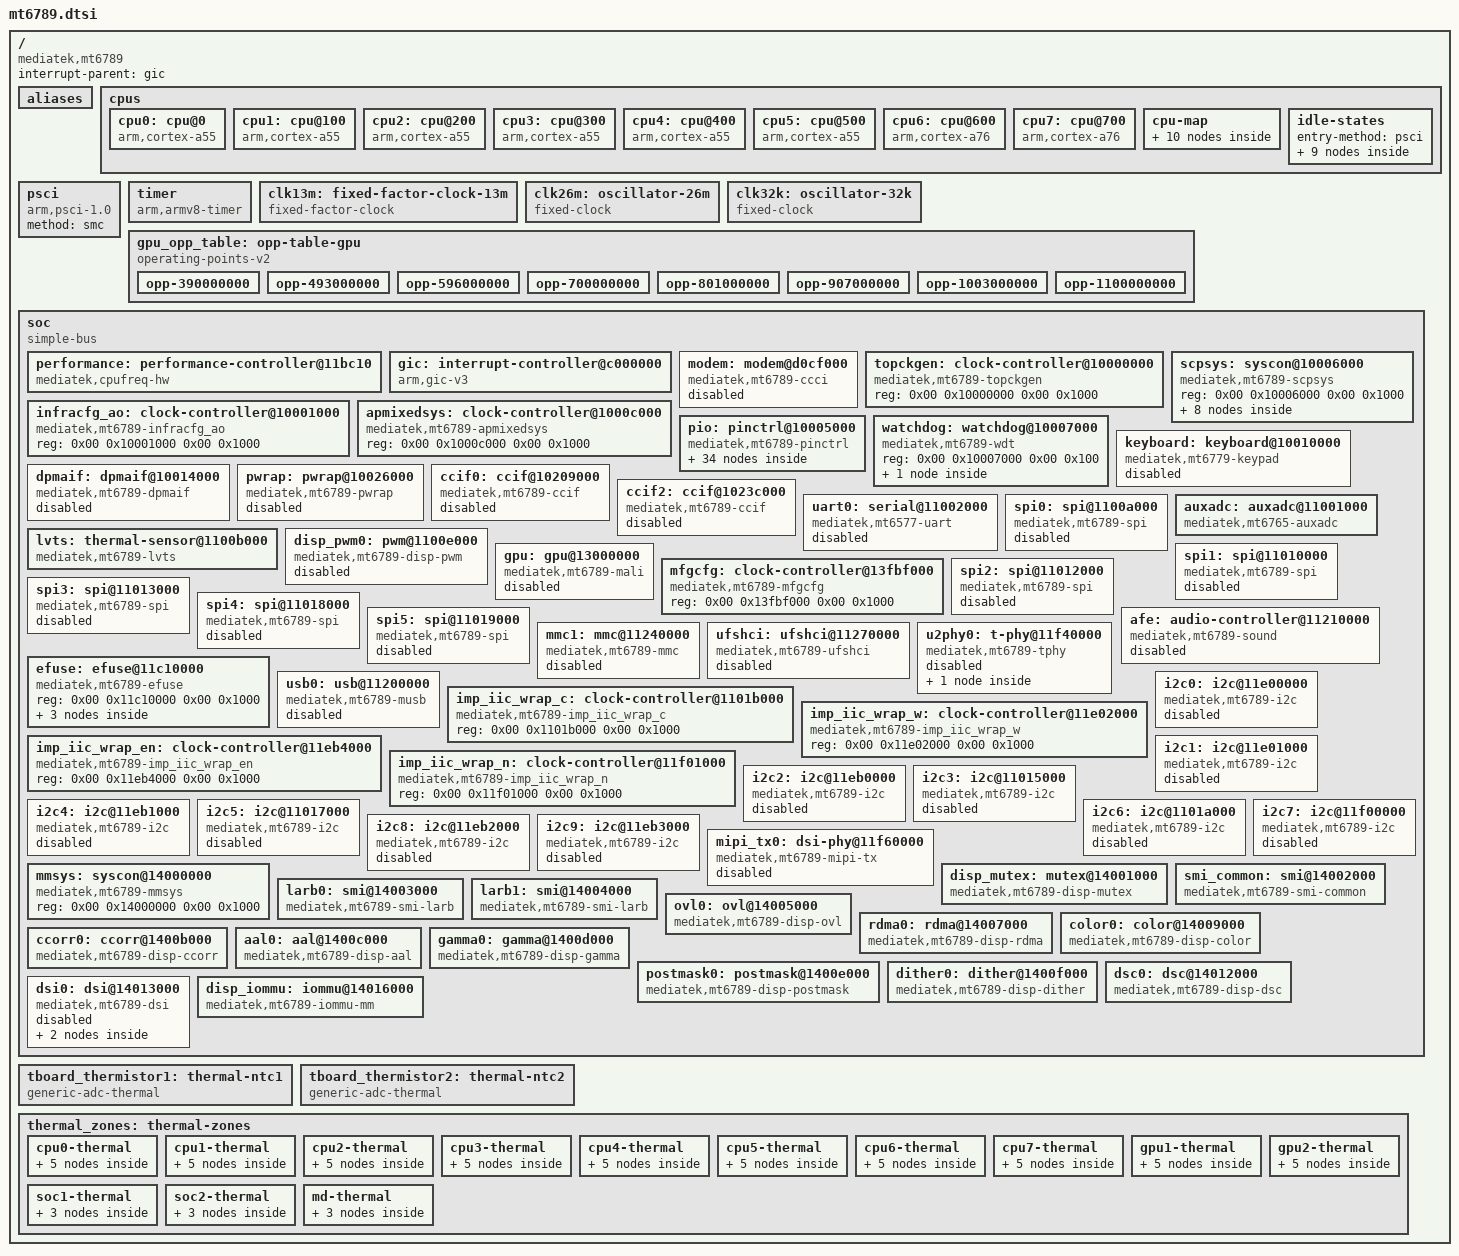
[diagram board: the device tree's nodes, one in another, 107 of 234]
// SPDX-License-Identifier: GPL-2.0-or-later
/*
 * MediaTek MT6789 (Helio G99) SoC base device tree — mainline shape.
 *
 * Board authority: Advan X1 stock artifacts (extracted/v5/dtb/main_dtb_0.dts,
 * dtbo_unpacked.dts). Every address/IRQ here is copied from those files; the
 * structure follows upstream mediatek dtsi conventions (mt8186 generation).
 *
 * P1 scope: CPU topology, GICv3, arch timer, PSCI, watchdog, UART0, and the
 * three clock controllers (topckgen, apmixedsys, infracfg_ao). UFS/USB/mphy/
 * scpsys nodes land in P2-P4 with their drivers.
 */

#include <dt-bindings/interrupt-controller/arm-gic.h>
#include <dt-bindings/interrupt-controller/irq.h>
#include <dt-bindings/clock/mt6789-clk.h>
#include <dt-bindings/memory/mediatek,mt6789-memory-port.h>
#include <dt-bindings/reset/mt6789-resets.h>
#include <dt-bindings/phy/phy.h>
#include <dt-bindings/pinctrl/mt65xx.h>
#include <dt-bindings/pinctrl/mt6789-pinfunc.h>
#include <dt-bindings/power/mt6789-power.h>
#include <dt-bindings/thermal/thermal.h>
#include <dt-bindings/thermal/mediatek,lvts-thermal.h>

/ {
	compatible = "mediatek,mt6789";
	interrupt-parent = <&gic>;
	#address-cells = <2>;
	#size-cells = <2>;

	aliases {
		serial0 = &uart0;
		spi0 = &spi0;
		spi1 = &spi1;
		spi2 = &spi2;
		spi3 = &spi3;
		spi4 = &spi4;
		spi5 = &spi5;
		ovl0 = &ovl0;
		rdma0 = &rdma0;
		color0 = &color0;
		ccorr0 = &ccorr0;
		aal0 = &aal0;
		gamma0 = &gamma0;
		postmask0 = &postmask0;
		dither0 = &dither0;
		dsi0 = &dsi0;
		mutex0 = &disp_mutex;
	};

	cpus {
		#address-cells = <1>;
		#size-cells = <0>;

		/*
		 * 6x Cortex-A55 (MPIDR 0x0-0x5, cluster 0) and
		 * 2x Cortex-A76 (MPIDR 0x6-0x7, cluster 1).
		 */
		cpu0: cpu@0 {
			device_type = "cpu";
			compatible = "arm,cortex-a55";
			reg = <0x000>;
			enable-method = "psci";
			capacity-dmips-mhz = <383>;
			performance-domains = <&performance 0>;
			cpu-idle-states = <&cpuoff_l &clusteroff_l &mcusysoff
					   &system_mem &system_pll &system_bus
					   &s2idle>;
			#cooling-cells = <2>;
		};

		cpu1: cpu@100 {
			device_type = "cpu";
			compatible = "arm,cortex-a55";
			reg = <0x100>;
			enable-method = "psci";
			capacity-dmips-mhz = <383>;
			performance-domains = <&performance 0>;
			cpu-idle-states = <&cpuoff_l &clusteroff_l &mcusysoff
					   &system_mem &system_pll &system_bus
					   &s2idle>;
			#cooling-cells = <2>;
		};

		cpu2: cpu@200 {
			device_type = "cpu";
			compatible = "arm,cortex-a55";
			reg = <0x200>;
			enable-method = "psci";
			capacity-dmips-mhz = <383>;
			performance-domains = <&performance 0>;
			cpu-idle-states = <&cpuoff_l &clusteroff_l &mcusysoff
					   &system_mem &system_pll &system_bus
					   &s2idle>;
			#cooling-cells = <2>;
		};

		cpu3: cpu@300 {
			device_type = "cpu";
			compatible = "arm,cortex-a55";
			reg = <0x300>;
			enable-method = "psci";
			capacity-dmips-mhz = <383>;
			performance-domains = <&performance 0>;
			cpu-idle-states = <&cpuoff_l &clusteroff_l &mcusysoff
					   &system_mem &system_pll &system_bus
					   &s2idle>;
			#cooling-cells = <2>;
		};

		cpu4: cpu@400 {
			device_type = "cpu";
			compatible = "arm,cortex-a55";
			reg = <0x400>;
			enable-method = "psci";
			capacity-dmips-mhz = <383>;
			performance-domains = <&performance 0>;
			cpu-idle-states = <&cpuoff_l &clusteroff_l &mcusysoff
					   &system_mem &system_pll &system_bus
					   &s2idle>;
			#cooling-cells = <2>;
		};

		cpu5: cpu@500 {
			device_type = "cpu";
			compatible = "arm,cortex-a55";
			reg = <0x500>;
			enable-method = "psci";
			capacity-dmips-mhz = <383>;
			performance-domains = <&performance 0>;
			cpu-idle-states = <&cpuoff_l &clusteroff_l &mcusysoff
					   &system_mem &system_pll &system_bus
					   &s2idle>;
			#cooling-cells = <2>;
		};

		cpu6: cpu@600 {
			device_type = "cpu";
			compatible = "arm,cortex-a76";
			reg = <0x600>;
			enable-method = "psci";
			capacity-dmips-mhz = <1024>;
			performance-domains = <&performance 1>;
			cpu-idle-states = <&cpuoff_b &clusteroff_b &mcusysoff
					   &system_mem &system_pll &system_bus
					   &s2idle>;
			#cooling-cells = <2>;
		};

		cpu7: cpu@700 {
			device_type = "cpu";
			compatible = "arm,cortex-a76";
			reg = <0x700>;
			enable-method = "psci";
			capacity-dmips-mhz = <1024>;
			performance-domains = <&performance 1>;
			cpu-idle-states = <&cpuoff_b &clusteroff_b &mcusysoff
					   &system_mem &system_pll &system_bus
					   &s2idle>;
			#cooling-cells = <2>;
		};

		cpu-map {
			cluster0 {
				core0 { cpu = <&cpu0>; };
				core1 { cpu = <&cpu1>; };
				core2 { cpu = <&cpu2>; };
				core3 { cpu = <&cpu3>; };
				core4 { cpu = <&cpu4>; };
				core5 { cpu = <&cpu5>; };
			};

			cluster1 {
				core0 { cpu = <&cpu6>; };
				core1 { cpu = <&cpu7>; };
			};
		};

		idle-states {
			entry-method = "psci";

			cpuoff_l: cpu-off-l {
				compatible = "arm,idle-state";
				arm,psci-suspend-param = <0x00010001>;
				local-timer-stop;
				entry-latency-us = <50>;
				exit-latency-us = <100>;
				min-residency-us = <1600>;
			};

			cpuoff_b: cpu-off-b {
				compatible = "arm,idle-state";
				arm,psci-suspend-param = <0x00010002>;
				local-timer-stop;
				entry-latency-us = <50>;
				exit-latency-us = <100>;
				min-residency-us = <1400>;
			};

			clusteroff_l: cluster-off-l {
				compatible = "arm,idle-state";
				arm,psci-suspend-param = <0x01010101>;
				local-timer-stop;
				entry-latency-us = <100>;
				exit-latency-us = <250>;
				min-residency-us = <2100>;
			};

			clusteroff_b: cluster-off-b {
				compatible = "arm,idle-state";
				arm,psci-suspend-param = <0x01010102>;
				local-timer-stop;
				entry-latency-us = <100>;
				exit-latency-us = <250>;
				min-residency-us = <1900>;
			};

			mcusysoff: cluster-mcusys-off {
				compatible = "arm,idle-state";
				arm,psci-suspend-param = <0x01010701>;
				local-timer-stop;
				entry-latency-us = <450>;
				exit-latency-us = <600>;
				min-residency-us = <4000>;
			};

			system_mem: cluster-system-mem {
				compatible = "arm,idle-state";
				arm,psci-suspend-param = <0x01010f01>;
				local-timer-stop;
				entry-latency-us = <700>;
				exit-latency-us = <850>;
				min-residency-us = <4000>;
			};

			system_pll: cluster-system-pll {
				compatible = "arm,idle-state";
				arm,psci-suspend-param = <0x01010f02>;
				local-timer-stop;
				entry-latency-us = <800>;
				exit-latency-us = <950>;
				min-residency-us = <4000>;
			};

			system_bus: cluster-system-bus {
				compatible = "arm,idle-state";
				arm,psci-suspend-param = <0x01010f03>;
				local-timer-stop;
				entry-latency-us = <1300>;
				exit-latency-us = <2800>;
				min-residency-us = <4000>;
			};

			s2idle: cluster-s2idle {
				compatible = "arm,idle-state";
				arm,psci-suspend-param = <0x01011f01>;
				local-timer-stop;
				entry-latency-us = <10000>;
				exit-latency-us = <10000>;
				min-residency-us = <0xffffffff>;
			};
		};
	};

	psci {
		compatible = "arm,psci-1.0", "arm,psci-0.2";
		method = "smc";
	};

	timer {
		compatible = "arm,armv8-timer";
		interrupt-parent = <&gic>;
		interrupts = <GIC_PPI 13 (GIC_CPU_MASK_SIMPLE(8) | IRQ_TYPE_LEVEL_LOW)>,
			     <GIC_PPI 14 (GIC_CPU_MASK_SIMPLE(8) | IRQ_TYPE_LEVEL_LOW)>,
			     <GIC_PPI 11 (GIC_CPU_MASK_SIMPLE(8) | IRQ_TYPE_LEVEL_LOW)>,
			     <GIC_PPI 10 (GIC_CPU_MASK_SIMPLE(8) | IRQ_TYPE_LEVEL_LOW)>;
		/* LK leaves the counter at 13 MHz (verified 2026-11-11). */
		clock-frequency = <13000000>;
	};

	clk13m: fixed-factor-clock-13m {
		compatible = "fixed-factor-clock";
		#clock-cells = <0>;
		clocks = <&clk26m>;
		clock-div = <2>;
		clock-mult = <1>;
		clock-output-names = "clk13m";
	};

	clk26m: oscillator-26m {
		compatible = "fixed-clock";
		#clock-cells = <0>;
		clock-frequency = <26000000>;
		clock-output-names = "clk26m";
	};

	clk32k: oscillator-32k {
		compatible = "fixed-clock";
		#clock-cells = <0>;
		clock-frequency = <32768>;
		clock-output-names = "clk32k";
	};

	gpu_opp_table: opp-table-gpu {
		compatible = "operating-points-v2";

		opp-390000000 {
			opp-hz = /bits/ 64 <390000000>;
			opp-microvolt = <675000>;
		};

		opp-493000000 {
			opp-hz = /bits/ 64 <493000000>;
			opp-microvolt = <687500>;
		};

		opp-596000000 {
			opp-hz = /bits/ 64 <596000000>;
			opp-microvolt = <693750>;
		};

		opp-700000000 {
			opp-hz = /bits/ 64 <700000000>;
			opp-microvolt = <700000>;
		};

		opp-801000000 {
			opp-hz = /bits/ 64 <801000000>;
			opp-microvolt = <756250>;
		};

		opp-907000000 {
			opp-hz = /bits/ 64 <907000000>;
			opp-microvolt = <806250>;
		};

		opp-1003000000 {
			opp-hz = /bits/ 64 <1003000000>;
			opp-microvolt = <856250>;
		};

		opp-1100000000 {
			opp-hz = /bits/ 64 <1100000000>;
			opp-microvolt = <900000>;
		};
	};

	soc: soc {
		compatible = "simple-bus";
		#address-cells = <2>;
		#size-cells = <2>;
		ranges;

		performance: performance-controller@11bc10 {
			compatible = "mediatek,cpufreq-hw";
			reg = <0x00 0x0011bc10 0x00 0x120>,
			      <0x00 0x0011bd30 0x00 0x120>;
			#performance-domain-cells = <1>;
		};

		gic: interrupt-controller@c000000 {
			compatible = "arm,gic-v3";
			#interrupt-cells = <3>;
			#address-cells = <2>;
			#size-cells = <2>;
			interrupt-controller;
			reg = <0x00 0x0c000000 0x00 0x00040000>, /* GICD */
			      <0x00 0x0c040000 0x00 0x00200000>; /* GICR */
			interrupts = <GIC_PPI 9 (GIC_CPU_MASK_SIMPLE(8) | IRQ_TYPE_LEVEL_HIGH)>;
		};

		modem: modem@d0cf000 {
			compatible = "mediatek,mt6789-ccci";
			reg = <0x00 0x0d0cf000 0x00 0x1000>;
			reg-names = "md-rgu";
			interrupts = <GIC_SPI 110 IRQ_TYPE_EDGE_RISING>;
			interrupt-names = "md-wdt";
			power-domains = <&spm MT6789_POWER_DOMAIN_MD>;
			mediatek,ccif = <&ccif0>;
			mediatek,ccif-scp = <&ccif2>;
			mediatek,dpmaif = <&dpmaif>;
			mediatek,scpsys = <&scpsys>;
			mediatek,infracfg = <&infracfg_ao>;
			mediatek,srclken-o1 = <0x200000>;
			mediatek,power-flow-config = <0x12>;
			status = "disabled";
		};

		topckgen: clock-controller@10000000 {
			compatible = "mediatek,mt6789-topckgen", "syscon";
			reg = <0x00 0x10000000 0x00 0x1000>;
			#clock-cells = <1>;
		};

		infracfg_ao: clock-controller@10001000 {
			compatible = "mediatek,mt6789-infracfg_ao", "syscon";
			reg = <0x00 0x10001000 0x00 0x1000>;
			#clock-cells = <1>;
			#reset-cells = <1>;
		};

		scpsys: syscon@10006000 {
			compatible = "mediatek,mt6789-scpsys", "syscon", "simple-mfd";
			reg = <0x00 0x10006000 0x00 0x1000>;

			/* System Power Manager */
			spm: power-controller {
				compatible = "mediatek,mt6789-power-controller";
				#address-cells = <1>;
				#size-cells = <0>;
				#power-domain-cells = <1>;

				/* power domain of the SoC */
				md: power-domain@0 {
					reg = <MT6789_POWER_DOMAIN_MD>;
					mediatek,infracfg = <&infracfg_ao>;
					#power-domain-cells = <0>;
				};

				mfg0: power-domain@2 {
					reg = <MT6789_POWER_DOMAIN_MFG0>;
					clocks = <&topckgen CLK_TOP_MFG_PLL_SEL>,
						 <&topckgen CLK_TOP_MFG_REF_SEL>;
					clock-names = "mfg", "alt";
					#address-cells = <1>;
					#size-cells = <0>;
					#power-domain-cells = <1>;

					mfg1: power-domain@3 {
						reg = <MT6789_POWER_DOMAIN_MFG1>;
						mediatek,infracfg = <&infracfg_ao>;
						#address-cells = <1>;
						#size-cells = <0>;
						#power-domain-cells = <1>;

						mfg2: power-domain@4 {
							reg = <MT6789_POWER_DOMAIN_MFG2>;
							#power-domain-cells = <0>;
						};

						mfg3: power-domain@5 {
							reg = <MT6789_POWER_DOMAIN_MFG3>;
							#power-domain-cells = <0>;
						};
					};
				};

				power-domain@10 {
					reg = <MT6789_POWER_DOMAIN_DISP>;
					clocks = <&topckgen CLK_TOP_DISP_SEL>,
						 <&mmsys CLK_MM_SMI_INFRA>,
						 <&mmsys CLK_MM_SMI_COMMON>,
						 <&mmsys CLK_MM_SMI_GALS>,
						 <&mmsys CLK_MM_SMI_IOMMU>,
						 <&mmsys CLK_MM_APB_BUS>,
						 <&mmsys CLK_MM_DISP_26M>;
					clock-names = "disp",
						      "subsys-smi-infra",
						      "subsys-smi-common",
						      "subsys-smi-gals",
						      "subsys-smi-iommu",
						      "subsys-apb-bus",
						      "subsys-disp-26m";
					mediatek,infracfg = <&infracfg_ao>;
					#power-domain-cells = <0>;
				};

				power-domain@11 {
					reg = <MT6789_POWER_DOMAIN_AUDIO>;
					clocks = <&topckgen CLK_TOP_AUD_INTBUS_SEL>,
						 <&infracfg_ao CLK_IFRAO_AUDIO_26M_BCLK>,
						 <&infracfg_ao CLK_IFRAO_AUDIO>;
					clock-names = "audio",
						      "subsys-audio-0",
						      "subsys-audio-1";
					mediatek,infracfg = <&infracfg_ao>;
					#power-domain-cells = <0>;
				};
			};
		};

		apmixedsys: clock-controller@1000c000 {
			compatible = "mediatek,mt6789-apmixedsys", "syscon";
			reg = <0x00 0x1000c000 0x00 0x1000>;
			#clock-cells = <1>;
		};

		pio: pinctrl@10005000 {
			compatible = "mediatek,mt6789-pinctrl";
			reg = <0x00 0x10005000 0x00 0x1000>,
			      <0x00 0x11c30000 0x00 0x1000>,
			      <0x00 0x11d10000 0x00 0x1000>,
			      <0x00 0x11d40000 0x00 0x1000>,
			      <0x00 0x11e20000 0x00 0x1000>,
			      <0x00 0x11e60000 0x00 0x1000>,
			      <0x00 0x11ea0000 0x00 0x1000>,
			      <0x00 0x1000b000 0x00 0x1000>;
			reg-names = "gpio",
				    "iocfg_rb",
				    "iocfg_bm",
				    "iocfg_br",
				    "iocfg_lm",
				    "iocfg_bl",
				    "iocfg_rt",
				    "eint";
			gpio-controller;
			#gpio-cells = <2>;
			gpio-ranges = <&pio 0 0 188>;
			interrupt-controller;
			#interrupt-cells = <2>;
			interrupts = <GIC_SPI 244 IRQ_TYPE_LEVEL_HIGH>;

			spi0_pins: spi0-default-pins {
				pins-bus {
					pinmux = <PINMUX_GPIO30__FUNC_SPI0_CLK>,
						 <PINMUX_GPIO31__FUNC_SPI0_CSB>,
						 <PINMUX_GPIO32__FUNC_SPI0_MO>,
						 <PINMUX_GPIO33__FUNC_SPI0_MI>;
					drive-strength = <2>;
					bias-disable;
				};
			};

			spi1_pins: spi1-default-pins {
				pins-bus {
					pinmux = <PINMUX_GPIO34__FUNC_SPI1_CLK>,
						 <PINMUX_GPIO35__FUNC_SPI1_CSB>,
						 <PINMUX_GPIO36__FUNC_SPI1_MO>,
						 <PINMUX_GPIO37__FUNC_SPI1_MI>;
					bias-disable;
				};
			};

			spi2_pins: spi2-default-pins {
				pins-bus {
					pinmux = <PINMUX_GPIO38__FUNC_SPI2_CLK>,
						 <PINMUX_GPIO39__FUNC_SPI2_CSB>,
						 <PINMUX_GPIO40__FUNC_SPI2_MO>,
						 <PINMUX_GPIO41__FUNC_SPI2_MI>;
					bias-disable;
				};
			};

			spi3_pins: spi3-default-pins {
				pins-bus {
					pinmux = <PINMUX_GPIO42__FUNC_SPI3_CLK>,
						 <PINMUX_GPIO43__FUNC_SPI3_CSB>,
						 <PINMUX_GPIO44__FUNC_SPI3_MO>,
						 <PINMUX_GPIO45__FUNC_SPI3_MI>;
					bias-disable;
				};
			};

			spi4_pins: spi4-default-pins {
				pins-bus {
					pinmux = <PINMUX_GPIO9__FUNC_SPI4_CLK>,
						 <PINMUX_GPIO10__FUNC_SPI4_CSB>,
						 <PINMUX_GPIO11__FUNC_SPI4_MO>,
						 <PINMUX_GPIO12__FUNC_SPI4_MI>;
					bias-disable;
				};
			};

			spi5_pins: spi5-default-pins {
				pins-bus {
					pinmux = <PINMUX_GPIO46__FUNC_SPI5_CLK>,
						 <PINMUX_GPIO47__FUNC_SPI5_CSB>,
						 <PINMUX_GPIO48__FUNC_SPI5_MO>,
						 <PINMUX_GPIO49__FUNC_SPI5_MI>;
					bias-disable;
				};
			};

			i2c0_pins: i2c0-default-pins {
				pins-bus {
					pinmux = <PINMUX_GPIO130__FUNC_SCL0>,
						 <PINMUX_GPIO131__FUNC_SDA0>;
					bias-pull-up = <MTK_PULL_SET_RSEL_011>;
					input-enable;
				};
			};

			i2c1_pins: i2c1-default-pins {
				pins-bus {
					pinmux = <PINMUX_GPIO132__FUNC_SCL1>,
						 <PINMUX_GPIO133__FUNC_SDA1>;
					bias-pull-up = <MTK_PULL_SET_RSEL_011>;
					input-enable;
				};
			};

			i2c2_pins: i2c2-default-pins {
				pins-bus {
					pinmux = <PINMUX_GPIO134__FUNC_SCL2>,
						 <PINMUX_GPIO135__FUNC_SDA2>;
					bias-pull-up = <MTK_PULL_SET_RSEL_011>;
					input-enable;
				};
			};

			i2c3_pins: i2c3-default-pins {
				pins-bus {
					pinmux = <PINMUX_GPIO136__FUNC_SCL3>,
						 <PINMUX_GPIO137__FUNC_SDA3>;
					bias-pull-up = <MTK_PULL_SET_RSEL_011>;
					input-enable;
				};
			};

			i2c4_pins: i2c4-default-pins {
				pins-bus {
					pinmux = <PINMUX_GPIO138__FUNC_SCL4>,
						 <PINMUX_GPIO139__FUNC_SDA4>;
					bias-pull-up = <MTK_PULL_SET_RSEL_011>;
					input-enable;
				};
			};

			i2c5_pins: i2c5-default-pins {
				pins-bus {
					pinmux = <PINMUX_GPIO140__FUNC_SCL5>,
						 <PINMUX_GPIO141__FUNC_SDA5>;
					bias-pull-up = <MTK_PULL_SET_RSEL_011>;
					input-enable;
				};
			};

			i2c6_pins: i2c6-default-pins {
				pins-bus {
					pinmux = <PINMUX_GPIO142__FUNC_SCL6>,
						 <PINMUX_GPIO143__FUNC_SDA6>;
					bias-pull-up = <MTK_PULL_SET_RSEL_011>;
					input-enable;
				};
			};

			i2c7_pins: i2c7-default-pins {
				pins-bus {
					pinmux = <PINMUX_GPIO144__FUNC_SCL7>,
						 <PINMUX_GPIO145__FUNC_SDA7>;
					bias-pull-up = <MTK_PULL_SET_RSEL_011>;
					input-enable;
				};
			};

			i2c8_pins: i2c8-default-pins {
				pins-bus {
					pinmux = <PINMUX_GPIO146__FUNC_SCL8>,
						 <PINMUX_GPIO147__FUNC_SDA8>;
					bias-pull-up = <MTK_PULL_SET_RSEL_011>;
					input-enable;
				};
			};

			i2c9_pins: i2c9-default-pins {
				pins-bus {
					pinmux = <PINMUX_GPIO148__FUNC_SCL9>,
						 <PINMUX_GPIO149__FUNC_SDA9>;
					bias-pull-up = <MTK_PULL_SET_RSEL_011>;
					input-enable;
				};
			};

			disp_pwm0_pins: disp-pwm0-default-pins {
				pins-bus {
					pinmux = <PINMUX_GPIO84__FUNC_DISP_PWM>;
				};
			};
		};

		watchdog: watchdog@10007000 {
			compatible = "mediatek,mt6789-wdt", "mediatek,mt6589-wdt",
				     "syscon", "simple-mfd";
			reg = <0x00 0x10007000 0x00 0x100>;
			#reset-cells = <1>;

			reboot-mode {
				compatible = "syscon-reboot-mode";
				offset = <0x24>;
				mask = <0x0f>;
				mode-charger = <0x01>;
				mode-recovery = <0x02>;
				mode-bootloader = <0x03>;
				mode-dm-verity-dev-corrupt = <0x04>;
				mode-kpoc = <0x05>;
				mode-ddr-reserve = <0x06>;
				mode-meta = <0x07>;
				mode-rpmbpk = <0x08>;
			};
		};

		keyboard: keyboard@10010000 {
			compatible = "mediatek,mt6779-keypad";
			reg = <0x00 0x10010000 0x00 0x1000>;
			interrupts = <GIC_SPI 106 IRQ_TYPE_EDGE_RISING>;
			clocks = <&clk26m>;
			clock-names = "kpd";
			status = "disabled";
		};

		dpmaif: dpmaif@10014000 {
			compatible = "mediatek,mt6789-dpmaif";
			reg = <0x00 0x10014000 0x00 0x1000>,
			      <0x00 0x10014400 0x00 0x1000>,
			      <0x00 0x1022d000 0x00 0x1000>,
			      <0x00 0x1022d100 0x00 0x1000>,
			      <0x00 0x1022d400 0x00 0x1000>,
			      <0x00 0x1022c000 0x00 0x1000>,
			      <0x00 0x1022e000 0x00 0x1000>;
			reg-names = "ao-ul", "ao-dl", "pd-ul", "pd-dl",
				    "pd-misc", "pd-md-misc", "pd-sram";
			interrupts = <GIC_SPI 241 IRQ_TYPE_LEVEL_HIGH>;
			clocks = <&infracfg_ao CLK_IFRAO_DPMAIF_MAIN>,
				 <&infracfg_ao CLK_IFRAO_CLDMA_BCLK>;
			clock-names = "dpmaif", "bclk";
			status = "disabled";
		};

		pwrap: pwrap@10026000 {
			compatible = "mediatek,mt6789-pwrap", "syscon";
			reg = <0x00 0x10026000 0x00 0x1000>;
			reg-names = "pwrap";
			interrupts = <GIC_SPI 252 IRQ_TYPE_LEVEL_HIGH>;
			clocks = <&infracfg_ao CLK_IFRAO_PMIC_AP>,
				 <&infracfg_ao CLK_IFRAO_PMIC_TMR>;
			clock-names = "spi", "wrap";
			status = "disabled";
		};

		ccif0: ccif@10209000 {
			compatible = "mediatek,mt6789-ccif";
			reg = <0x00 0x10209000 0x00 0x1000>,
			      <0x00 0x1020a000 0x00 0x1000>;
			reg-names = "ap", "md";
			interrupts = <GIC_SPI 226 IRQ_TYPE_LEVEL_HIGH>,
				     <GIC_SPI 227 IRQ_TYPE_LEVEL_HIGH>;
			clocks = <&infracfg_ao CLK_IFRAO_CCIF_AP>,
				 <&infracfg_ao CLK_IFRAO_CCIF_MD>,
				 <&infracfg_ao CLK_IFRAO_CCIF1_AP>,
				 <&infracfg_ao CLK_IFRAO_CCIF1_MD>,
				 <&infracfg_ao CLK_IFRAO_CCIF4_MD>,
				 <&infracfg_ao CLK_IFRAO_CCIF5_MD>;
			clock-names = "ccif-ap", "ccif-md", "ccif1-ap",
				      "ccif1-md", "ccif4-md", "ccif5-md";
			mediatek,ccif-sram-size = <0x200>;
			status = "disabled";
		};

		ccif2: ccif@1023c000 {
			compatible = "mediatek,mt6789-ccif";
			reg = <0x00 0x1023c000 0x00 0x1000>,
			      <0x00 0x1023d000 0x00 0x1000>;
			reg-names = "ap", "md";
			clocks = <&infracfg_ao CLK_IFRAO_CCIF2_AP>,
				 <&infracfg_ao CLK_IFRAO_CCIF2_MD>;
			clock-names = "ccif2-ap", "ccif2-md";
			status = "disabled";
		};

		uart0: serial@11002000 {
			compatible = "mediatek,mt6577-uart";
			reg = <0x00 0x11002000 0x00 0x1000>;
			interrupts = <GIC_SPI 141 IRQ_TYPE_LEVEL_HIGH>;
			clocks = <&clk26m>, <&infracfg_ao CLK_IFRAO_UART0>;
			clock-names = "baud", "bus";
			status = "disabled";
		};

		spi0: spi@1100a000 {
			compatible = "mediatek,mt6789-spi", "mediatek,mt6765-spi";
			#address-cells = <1>;
			#size-cells = <0>;
			reg = <0x00 0x1100a000 0x00 0x100>;
			interrupts = <GIC_SPI 191 IRQ_TYPE_LEVEL_HIGH>;
			clocks = <&topckgen CLK_TOP_MSDCPLL_D2>,
				 <&topckgen CLK_TOP_SPI_SEL>,
				 <&infracfg_ao CLK_IFRAO_SPI0>;
			clock-names = "parent-clk", "sel-clk", "spi-clk";
			mediatek,pad-select = <0>;
			status = "disabled";
		};

		auxadc: auxadc@11001000 {
			compatible = "mediatek,mt6765-auxadc";
			reg = <0x00 0x11001000 0x00 0x1000>;
			clocks = <&infracfg_ao CLK_IFRAO_AUXADC>;
			clock-names = "main";
			#io-channel-cells = <1>;
		};

		lvts: thermal-sensor@1100b000 {
			compatible = "mediatek,mt6789-lvts";
			reg = <0x00 0x1100b000 0x00 0x1000>;
			interrupts = <GIC_SPI 201 IRQ_TYPE_LEVEL_HIGH>;
			clocks = <&infracfg_ao CLK_IFRAO_THERM>;
			resets = <&infracfg_ao MT6789_INFRA_RST0_THERM_CTRL_SWRST>;
			nvmem-cells = <&lvts_e_data>;
			nvmem-cell-names = "lvts-calib-data-1";
			#thermal-sensor-cells = <1>;
		};

		disp_pwm0: pwm@1100e000 {
			compatible = "mediatek,mt6789-disp-pwm";
			reg = <0x00 0x1100e000 0x00 0x1000>;
			interrupts = <GIC_SPI 203 IRQ_TYPE_LEVEL_HIGH>;
			#pwm-cells = <2>;
			clocks = <&topckgen CLK_TOP_DISP_PWM>,
				 <&infracfg_ao CLK_IFRAO_DISP_PWM>;
			clock-names = "main", "mm";
			pinctrl-names = "default";
			pinctrl-0 = <&disp_pwm0_pins>;
			status = "disabled";
		};

		gpu: gpu@13000000 {
			compatible = "mediatek,mt6789-mali",
				     "arm,mali-valhall-jm";
			reg = <0x00 0x13000000 0x00 0x4000>;
			interrupts = <GIC_SPI 398 IRQ_TYPE_LEVEL_HIGH>,
				     <GIC_SPI 397 IRQ_TYPE_LEVEL_HIGH>,
				     <GIC_SPI 396 IRQ_TYPE_LEVEL_HIGH>;
			interrupt-names = "job", "mmu", "gpu";
			clocks = <&mfgcfg CLK_MFGCFG_BG3D>;
			power-domains = <&spm MT6789_POWER_DOMAIN_MFG2>,
					<&spm MT6789_POWER_DOMAIN_MFG3>;
			power-domain-names = "core0", "core1";
			operating-points-v2 = <&gpu_opp_table>;
			#cooling-cells = <2>;
			status = "disabled";
		};

		mfgcfg: clock-controller@13fbf000 {
			compatible = "mediatek,mt6789-mfgcfg", "syscon";
			reg = <0x00 0x13fbf000 0x00 0x1000>;
			#clock-cells = <1>;
		};

		spi1: spi@11010000 {
			compatible = "mediatek,mt6789-spi", "mediatek,mt6765-spi";
			#address-cells = <1>;
			#size-cells = <0>;
			reg = <0x00 0x11010000 0x00 0x100>;
			interrupts = <GIC_SPI 192 IRQ_TYPE_LEVEL_HIGH>;
			clocks = <&topckgen CLK_TOP_MSDCPLL_D2>,
				 <&topckgen CLK_TOP_SPI_SEL>,
				 <&infracfg_ao CLK_IFRAO_SPI1>;
			clock-names = "parent-clk", "sel-clk", "spi-clk";
			mediatek,pad-select = <0>;
			status = "disabled";
		};

		spi2: spi@11012000 {
			compatible = "mediatek,mt6789-spi", "mediatek,mt6765-spi";
			#address-cells = <1>;
			#size-cells = <0>;
			reg = <0x00 0x11012000 0x00 0x100>;
			interrupts = <GIC_SPI 193 IRQ_TYPE_LEVEL_HIGH>;
			clocks = <&topckgen CLK_TOP_MSDCPLL_D2>,
				 <&topckgen CLK_TOP_SPI_SEL>,
				 <&infracfg_ao CLK_IFRAO_SPI2>;
			clock-names = "parent-clk", "sel-clk", "spi-clk";
			mediatek,pad-select = <0>;
			status = "disabled";
		};

		spi3: spi@11013000 {
			compatible = "mediatek,mt6789-spi", "mediatek,mt6765-spi";
			#address-cells = <1>;
			#size-cells = <0>;
			reg = <0x00 0x11013000 0x00 0x100>;
			interrupts = <GIC_SPI 194 IRQ_TYPE_LEVEL_HIGH>;
			clocks = <&topckgen CLK_TOP_MSDCPLL_D2>,
				 <&topckgen CLK_TOP_SPI_SEL>,
				 <&infracfg_ao CLK_IFRAO_SPI3>;
			clock-names = "parent-clk", "sel-clk", "spi-clk";
			mediatek,pad-select = <0>;
			status = "disabled";
		};

		spi4: spi@11018000 {
			compatible = "mediatek,mt6789-spi", "mediatek,mt6765-spi";
			#address-cells = <1>;
			#size-cells = <0>;
			reg = <0x00 0x11018000 0x00 0x100>;
			interrupts = <GIC_SPI 195 IRQ_TYPE_LEVEL_HIGH>;
			clocks = <&topckgen CLK_TOP_MSDCPLL_D2>,
				 <&topckgen CLK_TOP_SPI_SEL>,
				 <&infracfg_ao CLK_IFRAO_SPI4>;
			clock-names = "parent-clk", "sel-clk", "spi-clk";
			mediatek,pad-select = <0>;
			status = "disabled";
		};

		spi5: spi@11019000 {
			compatible = "mediatek,mt6789-spi", "mediatek,mt6765-spi";
			#address-cells = <1>;
			#size-cells = <0>;
			reg = <0x00 0x11019000 0x00 0x100>;
			interrupts = <GIC_SPI 196 IRQ_TYPE_LEVEL_HIGH>;
			clocks = <&topckgen CLK_TOP_MSDCPLL_D2>,
				 <&topckgen CLK_TOP_SPI_SEL>,
				 <&infracfg_ao CLK_IFRAO_SPI5>;
			clock-names = "parent-clk", "sel-clk", "spi-clk";
			mediatek,pad-select = <0>;
			status = "disabled";
		};

		afe: audio-controller@11210000 {
			compatible = "mediatek,mt6789-sound";
			reg = <0x00 0x11210000 0x00 0x2000>;
			interrupts = <GIC_SPI 234 IRQ_TYPE_LEVEL_HIGH>;
			power-domains = <&spm MT6789_POWER_DOMAIN_AUDIO>;
			mediatek,apmixedsys = <&apmixedsys>;
			mediatek,infracfg = <&infracfg_ao>;
			mediatek,topckgen = <&topckgen>;
			clocks = <&infracfg_ao CLK_IFRAO_AUDIO>,
				 <&infracfg_ao CLK_IFRAO_AUDIO_26M_BCLK>,
				 <&topckgen CLK_TOP_AUDIO_SEL>,
				 <&topckgen CLK_TOP_AUD_INTBUS_SEL>,
				 <&topckgen CLK_TOP_MAINPLL_D4_D4>,
				 <&topckgen CLK_TOP_AUD_1_SEL>,
				 <&topckgen CLK_TOP_APLL1>,
				 <&topckgen CLK_TOP_AUD_2_SEL>,
				 <&topckgen CLK_TOP_APLL2>,
				 <&topckgen CLK_TOP_AUD_ENGEN1_SEL>,
				 <&topckgen CLK_TOP_APLL1_D8>,
				 <&topckgen CLK_TOP_AUD_ENGEN2_SEL>,
				 <&topckgen CLK_TOP_APLL2_D8>,
				 <&topckgen CLK_TOP_APLL_I2S0_MCK_SEL>,
				 <&topckgen CLK_TOP_APLL_I2S1_MCK_SEL>,
				 <&topckgen CLK_TOP_APLL_I2S2_MCK_SEL>,
				 <&topckgen CLK_TOP_APLL_I2S4_MCK_SEL>,
				 <&topckgen CLK_TOP_APLL_I2S5_MCK_SEL>,
				 <&topckgen CLK_TOP_APLL12_CK_DIV0>,
				 <&topckgen CLK_TOP_APLL12_CK_DIV1>,
				 <&topckgen CLK_TOP_APLL12_CK_DIV2>,
				 <&topckgen CLK_TOP_APLL12_CK_DIV4>,
				 <&topckgen CLK_TOP_APLL12_CK_DIV5>,
				 <&topckgen CLK_TOP_AUDIO_H_SEL>,
				 <&topckgen CLK_TOP_TCK_26M_MX9>;
			clock-names = "aud_infra_clk",
				      "mtkaif_26m_clk",
				      "top_mux_audio",
				      "top_mux_audio_int",
				      "top_mainpll_d2_d4",
				      "top_mux_aud_1",
				      "top_apll1_ck",
				      "top_mux_aud_2",
				      "top_apll2_ck",
				      "top_mux_aud_eng1",
				      "top_apll1_d8",
				      "top_mux_aud_eng2",
				      "top_apll2_d8",
				      "top_i2s0_m_sel",
				      "top_i2s1_m_sel",
				      "top_i2s2_m_sel",
				      "top_i2s4_m_sel",
				      "top_tdm_m_sel",
				      "top_apll12_div0",
				      "top_apll12_div1",
				      "top_apll12_div2",
				      "top_apll12_div4",
				      "top_apll12_div_tdm",
				      "top_mux_audio_h",
				      "top_clk26m_clk";
			status = "disabled";
		};

		mmc1: mmc@11240000 {
			compatible = "mediatek,mt6789-mmc", "mediatek,mt8183-mmc";
			reg = <0x00 0x11240000 0x00 0x1000>,
			      <0x00 0x11ef0000 0x00 0x1000>;
			interrupts = <GIC_SPI 135 IRQ_TYPE_LEVEL_HIGH>;
			clocks = <&topckgen CLK_TOP_MSDC30_1_SEL>,
				 <&infracfg_ao CLK_IFRAO_MSDC1>,
				 <&infracfg_ao CLK_IFRAO_MSDC1_SRC>;
			clock-names = "source", "hclk", "source_cg";
			assigned-clocks = <&topckgen CLK_TOP_MSDC30_1_SEL>;
			assigned-clock-parents = <&topckgen CLK_TOP_MSDCPLL_D2>;
			status = "disabled";
		};

		ufshci: ufshci@11270000 {
			compatible = "mediatek,mt6789-ufshci", "mediatek,mt8183-ufshci";
			reg = <0x00 0x11270000 0x00 0x2300>;
			interrupts = <GIC_SPI 137 IRQ_TYPE_LEVEL_HIGH>;
			clocks = <&infracfg_ao CLK_IFRAO_UFS>,
				 <&infracfg_ao CLK_IFRAO_UFS_SAP_BCLK>,
				 <&infracfg_ao CLK_IFRAO_UNIPRO_TICK>,
				 <&infracfg_ao CLK_IFRAO_UNIPRO_SYSCLK>,
				 <&infracfg_ao CLK_IFRAO_UFS_AES>,
				 <&topckgen CLK_TOP_AES_UFSFDE_SEL>,
				 <&topckgen CLK_TOP_UFS_SEL>;
			clock-names = "ufs", "ufs_mp", "unipro_tick",
				      "unipro_sys", "ufs_aes",
				      "ufsfde_ck", "ufs_ck";
			freq-table-hz = <0 0>, <0 0>, <0 0>, <0 0>, <0 0>,
					<0 0>, <0 0>;
			resets = <&infracfg_ao MT6789_INFRA_RST1_UFS_SWRST>,
				 <&infracfg_ao MT6789_INFRA_RST2_UFS_UNIPRO_SWRST>,
				 <&infracfg_ao MT6789_INFRA_RST3_UFS_AES_SWRST>;
			reset-names = "hci_rst", "unipro_rst", "crypto_rst";
			mediatek,ufs-disable-mcq;
			status = "disabled";
		};

		efuse: efuse@11c10000 {
			compatible = "mediatek,mt6789-efuse", "mediatek,efuse";
			reg = <0x00 0x11c10000 0x00 0x1000>;
			#address-cells = <1>;
			#size-cells = <1>;

			socinfo-data1@4c {
				reg = <0x4c 0x4>;
			};

			socinfo-data2@50 {
				reg = <0x50 0x4>;
			};

			lvts_e_data: lvts-calib@1a4 {
				reg = <0x1a4 0x34>;
			};
		};

		u2phy0: t-phy@11f40000 {
			compatible = "mediatek,mt6789-tphy", "mediatek,generic-tphy-v2";
			#address-cells = <1>;
			#size-cells = <1>;
			ranges = <0x0 0x0 0x11f40000 0x1000>;
			status = "disabled";

			u2port0: usb-phy@0 {
				reg = <0x0 0x700>;
				clocks = <&clk26m>;
				clock-names = "ref";
				#phy-cells = <1>;
				mediatek,eye-vrt = <4>;
				mediatek,eye-term = <4>;
				mediatek,discth = <7>;
			};
		};

		usb0: usb@11200000 {
			compatible = "mediatek,mt6789-musb", "mediatek,mtk-musb";
			reg = <0x00 0x11200000 0x00 0x10000>;
			interrupts = <GIC_SPI 128 IRQ_TYPE_LEVEL_HIGH>;
			interrupt-names = "mc";
			clocks = <&infracfg_ao CLK_IFRAO_SSUSB>,
				 <&topckgen CLK_TOP_USB_TOP_SEL>,
				 <&apmixedsys CLK_APMIXED_USBPLL>;
			clock-names = "main", "mcu", "univpll";
			phys = <&u2port0 PHY_TYPE_USB2>;
			dr_mode = "peripheral";
			status = "disabled";
		};

		imp_iic_wrap_c: clock-controller@1101b000 {
			compatible = "mediatek,mt6789-imp_iic_wrap_c", "syscon";
			reg = <0x00 0x1101b000 0x00 0x1000>;
			#clock-cells = <1>;
		};

		imp_iic_wrap_w: clock-controller@11e02000 {
			compatible = "mediatek,mt6789-imp_iic_wrap_w", "syscon";
			reg = <0x00 0x11e02000 0x00 0x1000>;
			#clock-cells = <1>;
		};

		imp_iic_wrap_en: clock-controller@11eb4000 {
			compatible = "mediatek,mt6789-imp_iic_wrap_en", "syscon";
			reg = <0x00 0x11eb4000 0x00 0x1000>;
			#clock-cells = <1>;
		};

		imp_iic_wrap_n: clock-controller@11f01000 {
			compatible = "mediatek,mt6789-imp_iic_wrap_n", "syscon";
			reg = <0x00 0x11f01000 0x00 0x1000>;
			#clock-cells = <1>;
		};

		i2c0: i2c@11e00000 {
			compatible = "mediatek,mt6789-i2c";
			reg = <0x00 0x11e00000 0x00 0x1000>,
			      <0x00 0x10217080 0x00 0x80>;
			interrupts = <GIC_SPI 144 IRQ_TYPE_LEVEL_HIGH>;
			clocks = <&imp_iic_wrap_w CLK_IMPW_AP_CLOCK_I2C0>,
				 <&infracfg_ao CLK_IFRAO_AP_DMA>;
			clock-names = "main", "dma";
			clock-div = <1>;
			#address-cells = <1>;
			#size-cells = <0>;
			status = "disabled";
		};

		i2c1: i2c@11e01000 {
			compatible = "mediatek,mt6789-i2c";
			reg = <0x00 0x11e01000 0x00 0x1000>,
			      <0x00 0x10217100 0x00 0x80>;
			interrupts = <GIC_SPI 145 IRQ_TYPE_LEVEL_HIGH>;
			clocks = <&imp_iic_wrap_w CLK_IMPW_AP_CLOCK_I2C1>,
				 <&infracfg_ao CLK_IFRAO_AP_DMA>;
			clock-names = "main", "dma";
			clock-div = <1>;
			#address-cells = <1>;
			#size-cells = <0>;
			status = "disabled";
		};

		i2c2: i2c@11eb0000 {
			compatible = "mediatek,mt6789-i2c";
			reg = <0x00 0x11eb0000 0x00 0x1000>,
			      <0x00 0x10217180 0x00 0x80>;
			interrupts = <GIC_SPI 146 IRQ_TYPE_LEVEL_HIGH>;
			clocks = <&imp_iic_wrap_en CLK_IMPEN_AP_CLOCK_I2C2>,
				 <&infracfg_ao CLK_IFRAO_AP_DMA>;
			clock-names = "main", "dma";
			clock-div = <1>;
			#address-cells = <1>;
			#size-cells = <0>;
			status = "disabled";
		};

		i2c3: i2c@11015000 {
			compatible = "mediatek,mt6789-i2c";
			reg = <0x00 0x11015000 0x00 0x1000>,
			      <0x00 0x10217280 0x00 0x80>;
			interrupts = <GIC_SPI 147 IRQ_TYPE_LEVEL_HIGH>;
			clocks = <&imp_iic_wrap_c CLK_IMPC_AP_CLOCK_I2C3>,
				 <&infracfg_ao CLK_IFRAO_AP_DMA>;
			clock-names = "main", "dma";
			clock-div = <1>;
			#address-cells = <1>;
			#size-cells = <0>;
			status = "disabled";
		};

		i2c4: i2c@11eb1000 {
			compatible = "mediatek,mt6789-i2c";
			reg = <0x00 0x11eb1000 0x00 0x1000>,
			      <0x00 0x10217300 0x00 0x80>;
			interrupts = <GIC_SPI 148 IRQ_TYPE_LEVEL_HIGH>;
			clocks = <&imp_iic_wrap_en CLK_IMPEN_AP_CLOCK_I2C4>,
				 <&infracfg_ao CLK_IFRAO_AP_DMA>;
			clock-names = "main", "dma";
			clock-div = <1>;
			#address-cells = <1>;
			#size-cells = <0>;
			status = "disabled";
		};

		i2c5: i2c@11017000 {
			compatible = "mediatek,mt6789-i2c";
			reg = <0x00 0x11017000 0x00 0x1000>,
			      <0x00 0x10217400 0x00 0x80>;
			interrupts = <GIC_SPI 149 IRQ_TYPE_LEVEL_HIGH>;
			clocks = <&imp_iic_wrap_c CLK_IMPC_AP_CLOCK_I2C5>,
				 <&infracfg_ao CLK_IFRAO_AP_DMA>;
			clock-names = "main", "dma";
			clock-div = <1>;
			#address-cells = <1>;
			#size-cells = <0>;
			status = "disabled";
		};

		i2c6: i2c@1101a000 {
			compatible = "mediatek,mt6789-i2c";
			reg = <0x00 0x1101a000 0x00 0x1000>,
			      <0x00 0x10217480 0x00 0x80>;
			interrupts = <GIC_SPI 150 IRQ_TYPE_LEVEL_HIGH>;
			clocks = <&imp_iic_wrap_c CLK_IMPC_AP_CLOCK_I2C6>,
				 <&infracfg_ao CLK_IFRAO_AP_DMA>;
			clock-names = "main", "dma";
			clock-div = <1>;
			#address-cells = <1>;
			#size-cells = <0>;
			status = "disabled";
		};

		i2c7: i2c@11f00000 {
			compatible = "mediatek,mt6789-i2c";
			reg = <0x00 0x11f00000 0x00 0x1000>,
			      <0x00 0x10217500 0x00 0x80>;
			interrupts = <GIC_SPI 151 IRQ_TYPE_LEVEL_HIGH>;
			clocks = <&imp_iic_wrap_n CLK_IMPN_AP_CLOCK_I2C7>,
				 <&infracfg_ao CLK_IFRAO_AP_DMA>;
			clock-names = "main", "dma";
			clock-div = <1>;
			#address-cells = <1>;
			#size-cells = <0>;
			status = "disabled";
		};

		i2c8: i2c@11eb2000 {
			compatible = "mediatek,mt6789-i2c";
			reg = <0x00 0x11eb2000 0x00 0x1000>,
			      <0x00 0x10217600 0x00 0x80>;
			interrupts = <GIC_SPI 152 IRQ_TYPE_LEVEL_HIGH>;
			clocks = <&imp_iic_wrap_en CLK_IMPEN_AP_CLOCK_I2C8>,
				 <&infracfg_ao CLK_IFRAO_AP_DMA>;
			clock-names = "main", "dma";
			clock-div = <1>;
			#address-cells = <1>;
			#size-cells = <0>;
			status = "disabled";
		};

		i2c9: i2c@11eb3000 {
			compatible = "mediatek,mt6789-i2c";
			reg = <0x00 0x11eb3000 0x00 0x1000>,
			      <0x00 0x10217700 0x00 0x80>;
			interrupts = <GIC_SPI 153 IRQ_TYPE_LEVEL_HIGH>;
			clocks = <&imp_iic_wrap_en CLK_IMPEN_AP_CLOCK_I2C9>,
				 <&infracfg_ao CLK_IFRAO_AP_DMA>;
			clock-names = "main", "dma";
			clock-div = <1>;
			#address-cells = <1>;
			#size-cells = <0>;
			status = "disabled";
		};

		mipi_tx0: dsi-phy@11f60000 {
			compatible = "mediatek,mt6789-mipi-tx", "mediatek,mt8183-mipi-tx";
			reg = <0x00 0x11f60000 0x00 0x1000>;
			clocks = <&clk26m>;
			#clock-cells = <0>;
			#phy-cells = <0>;
			clock-output-names = "mipi_tx0_pll";
			status = "disabled";
		};

		mmsys: syscon@14000000 {
			compatible = "mediatek,mt6789-mmsys", "syscon";
			reg = <0x00 0x14000000 0x00 0x1000>;
			#clock-cells = <1>;
			#reset-cells = <1>;
		};

		disp_mutex: mutex@14001000 {
			compatible = "mediatek,mt6789-disp-mutex";
			reg = <0x00 0x14001000 0x00 0x1000>;
			clocks = <&mmsys CLK_MM_DISP_MUTEX0>;
			interrupts = <GIC_SPI 285 IRQ_TYPE_LEVEL_HIGH>;
			power-domains = <&spm MT6789_POWER_DOMAIN_DISP>;
		};

		smi_common: smi@14002000 {
			compatible = "mediatek,mt6789-smi-common";
			reg = <0x00 0x14002000 0x00 0x1000>;
			clocks = <&mmsys CLK_MM_SMI_COMMON>,
				 <&mmsys CLK_MM_SMI_COMMON>,
				 <&mmsys CLK_MM_SMI_GALS>,
				 <&mmsys CLK_MM_SMI_GALS>;
			clock-names = "apb", "smi", "gals0", "gals1";
			power-domains = <&spm MT6789_POWER_DOMAIN_DISP>;
		};

		larb0: smi@14003000 {
			compatible = "mediatek,mt6789-smi-larb";
			reg = <0x00 0x14003000 0x00 0x1000>;
			clocks = <&mmsys CLK_MM_SMI_COMMON>,
				 <&mmsys CLK_MM_SMI_COMMON>;
			clock-names = "apb", "smi";
			mediatek,larb-id = <0>;
			mediatek,smi = <&smi_common>;
			power-domains = <&spm MT6789_POWER_DOMAIN_DISP>;
		};

		larb1: smi@14004000 {
			compatible = "mediatek,mt6789-smi-larb";
			reg = <0x00 0x14004000 0x00 0x1000>;
			clocks = <&mmsys CLK_MM_SMI_COMMON>,
				 <&mmsys CLK_MM_SMI_COMMON>;
			clock-names = "apb", "smi";
			mediatek,larb-id = <1>;
			mediatek,smi = <&smi_common>;
			power-domains = <&spm MT6789_POWER_DOMAIN_DISP>;
		};

		ovl0: ovl@14005000 {
			compatible = "mediatek,mt6789-disp-ovl", "mediatek,mt8192-disp-ovl";
			reg = <0x00 0x14005000 0x00 0x1000>;
			clocks = <&mmsys CLK_MM_DISP_OVL0>;
			interrupts = <GIC_SPI 287 IRQ_TYPE_LEVEL_HIGH>;
			iommus = <&disp_iommu M4U_PORT_L0_OVL_RDMA0_HDR>,
				 <&disp_iommu M4U_PORT_L0_OVL_RDMA0>;
			power-domains = <&spm MT6789_POWER_DOMAIN_DISP>;
		};

		rdma0: rdma@14007000 {
			compatible = "mediatek,mt6789-disp-rdma", "mediatek,mt8183-disp-rdma";
			reg = <0x00 0x14007000 0x00 0x1000>;
			clocks = <&mmsys CLK_MM_DISP_RDMA0>;
			interrupts = <GIC_SPI 289 IRQ_TYPE_LEVEL_HIGH>;
			iommus = <&disp_iommu M4U_PORT_L1_DISP_RDMA0>;
			power-domains = <&spm MT6789_POWER_DOMAIN_DISP>;
		};

		color0: color@14009000 {
			compatible = "mediatek,mt6789-disp-color", "mediatek,mt8173-disp-color";
			reg = <0x00 0x14009000 0x00 0x1000>;
			clocks = <&mmsys CLK_MM_DISP_COLOR0>;
			interrupts = <GIC_SPI 291 IRQ_TYPE_LEVEL_HIGH>;
			power-domains = <&spm MT6789_POWER_DOMAIN_DISP>;
		};

		ccorr0: ccorr@1400b000 {
			compatible = "mediatek,mt6789-disp-ccorr", "mediatek,mt8192-disp-ccorr";
			reg = <0x00 0x1400b000 0x00 0x1000>;
			clocks = <&mmsys CLK_MM_DISP_CCORR0>;
			interrupts = <GIC_SPI 292 IRQ_TYPE_LEVEL_HIGH>;
			power-domains = <&spm MT6789_POWER_DOMAIN_DISP>;
		};

		aal0: aal@1400c000 {
			compatible = "mediatek,mt6789-disp-aal", "mediatek,mt8183-disp-aal";
			reg = <0x00 0x1400c000 0x00 0x1000>;
			clocks = <&mmsys CLK_MM_DISP_AAL0>;
			interrupts = <GIC_SPI 294 IRQ_TYPE_LEVEL_HIGH>;
			power-domains = <&spm MT6789_POWER_DOMAIN_DISP>;
		};

		gamma0: gamma@1400d000 {
			compatible = "mediatek,mt6789-disp-gamma", "mediatek,mt8195-disp-gamma";
			reg = <0x00 0x1400d000 0x00 0x1000>;
			clocks = <&mmsys CLK_MM_DISP_GAMMA0>;
			interrupts = <GIC_SPI 295 IRQ_TYPE_LEVEL_HIGH>;
			power-domains = <&spm MT6789_POWER_DOMAIN_DISP>;
		};

		postmask0: postmask@1400e000 {
			compatible = "mediatek,mt6789-disp-postmask",
				     "mediatek,mt8192-disp-postmask";
			reg = <0x00 0x1400e000 0x00 0x1000>;
			clocks = <&mmsys CLK_MM_DISP_POSTMASK0>;
			interrupts = <GIC_SPI 296 IRQ_TYPE_LEVEL_HIGH>;
			power-domains = <&spm MT6789_POWER_DOMAIN_DISP>;
		};

		dither0: dither@1400f000 {
			compatible = "mediatek,mt6789-disp-dither", "mediatek,mt8183-disp-dither";
			reg = <0x00 0x1400f000 0x00 0x1000>;
			clocks = <&mmsys CLK_MM_DISP_DITHER0>;
			interrupts = <GIC_SPI 297 IRQ_TYPE_LEVEL_HIGH>;
			power-domains = <&spm MT6789_POWER_DOMAIN_DISP>;
		};

		dsc0: dsc@14012000 {
			compatible = "mediatek,mt6789-disp-dsc", "mediatek,mt8195-disp-dsc";
			reg = <0x00 0x14012000 0x00 0x1000>;
			clocks = <&mmsys CLK_MM_DISP_DSC_WRAP0>;
			interrupts = <GIC_SPI 300 IRQ_TYPE_LEVEL_HIGH>;
			power-domains = <&spm MT6789_POWER_DOMAIN_DISP>;
		};

		dsi0: dsi@14013000 {
			compatible = "mediatek,mt6789-dsi";
			reg = <0x00 0x14013000 0x00 0x1000>;
			clocks = <&mmsys CLK_MM_DSI0>,
				 <&mmsys CLK_MM_DSI0_DSI_CK_DOMAIN>,
				 <&mipi_tx0>;
			clock-names = "engine", "digital", "hs";
			interrupts = <GIC_SPI 301 IRQ_TYPE_LEVEL_HIGH>;
			power-domains = <&spm MT6789_POWER_DOMAIN_DISP>;
			phys = <&mipi_tx0>;
			phy-names = "dphy";
			status = "disabled";

			port {
				dsi0_out: endpoint {
				};
			};
		};

		disp_iommu: iommu@14016000 {
			compatible = "mediatek,mt6789-iommu-mm";
			reg = <0x00 0x14016000 0x00 0x1000>;
			interrupts = <GIC_SPI 303 IRQ_TYPE_LEVEL_HIGH>;
			clocks = <&mmsys CLK_MM_SMI_IOMMU>;
			clock-names = "bclk";
			power-domains = <&spm MT6789_POWER_DOMAIN_DISP>;
			mediatek,larbs = <&larb0>, <&larb1>;
			#iommu-cells = <1>;
		};
	};

	tboard_thermistor1: thermal-ntc1 {
		compatible = "generic-adc-thermal";
		#thermal-sensor-cells = <0>;
		io-channels = <&auxadc 0>;
		io-channel-names = "sensor-channel";
		temperature-lookup-table = <
			(-40000) 1760 (-39000) 1757 (-38000) 1754
			(-37000) 1751 (-36000) 1747 (-35000) 1744
			(-34000) 1740 (-33000) 1736 (-32000) 1731
			(-31000) 1727 (-30000) 1722 (-29000) 1716
			(-28000) 1711 (-27000) 1705 (-26000) 1699
			(-25000) 1693 (-24000) 1686 (-23000) 1679
			(-22000) 1672 (-21000) 1664 (-20000) 1656
			(-19000) 1648 (-18000) 1639 (-17000) 1630
			(-16000) 1620 (-15000) 1610 (-14000) 1599
			(-13000) 1588 (-12000) 1577 (-11000) 1565
			(-10000) 1553 (-9000) 1540 (-8000) 1527
			(-7000) 1514 (-6000) 1500 (-5000) 1485
			(-4000) 1470 (-3000) 1455 (-2000) 1439
			(-1000) 1423 (0) 1406 (1000) 1389
			(2000) 1372 (3000) 1354 (4000) 1335
			(5000) 1317 (6000) 1298 (7000) 1279
			(8000) 1259 (9000) 1239 (10000) 1219
			(11000) 1198 (12000) 1178 (13000) 1157
			(14000) 1136 (15000) 1115 (16000) 1093
			(17000) 1072 (18000) 1050 (19000) 1029
			(20000) 1007 (21000) 986 (22000) 964
			(23000) 943 (24000) 921 (25000) 900
			(26000) 879 (27000) 858 (28000) 837
			(29000) 816 (30000) 796 (31000) 775
			(32000) 755 (33000) 736 (34000) 716
			(35000) 697 (36000) 678 (37000) 659
			(38000) 641 (39000) 623 (40000) 605
			(41000) 588 (42000) 571 (43000) 555
			(44000) 538 (45000) 523 (46000) 507
			(47000) 492 (48000) 477 (49000) 463
			(50000) 449 (51000) 435 (52000) 422
			(53000) 409 (54000) 396 (55000) 384
			(56000) 372 (57000) 360 (58000) 349
			(59000) 338 (60000) 327 (61000) 317
			(62000) 307 (63000) 297 (64000) 288
			(65000) 279 (66000) 270 (67000) 261
			(68000) 253 (69000) 245 (70000) 237
			(71000) 230 (72000) 222 (73000) 215
			(74000) 209 (75000) 202 (76000) 196
			(77000) 189 (78000) 183 (79000) 178
			(80000) 172 (81000) 167 (82000) 161
			(83000) 156 (84000) 151 (85000) 147
			(86000) 142 (87000) 138 (88000) 133
			(89000) 129 (90000) 125 (91000) 121
			(92000) 118 (93000) 114 (94000) 111
			(95000) 107 (96000) 104 (97000) 101
			(98000) 98 (99000) 95 (100000) 92
			(101000) 89 (102000) 87 (103000) 84
			(104000) 81 (105000) 79 (106000) 77
			(107000) 74 (108000) 72 (109000) 70
			(110000) 68 (111000) 66 (112000) 64
			(113000) 62 (114000) 61 (115000) 59
			(116000) 57 (117000) 56 (118000) 54
			(119000) 52 (120000) 51 (121000) 50
			(122000) 48 (123000) 47 (124000) 46
			(125000) 44
		>;
	};

	tboard_thermistor2: thermal-ntc2 {
		compatible = "generic-adc-thermal";
		#thermal-sensor-cells = <0>;
		io-channels = <&auxadc 1>;
		io-channel-names = "sensor-channel";
		temperature-lookup-table = <
			(-40000) 1760 (-39000) 1757 (-38000) 1754
			(-37000) 1751 (-36000) 1747 (-35000) 1744
			(-34000) 1740 (-33000) 1736 (-32000) 1731
			(-31000) 1727 (-30000) 1722 (-29000) 1716
			(-28000) 1711 (-27000) 1705 (-26000) 1699
			(-25000) 1693 (-24000) 1686 (-23000) 1679
			(-22000) 1672 (-21000) 1664 (-20000) 1656
			(-19000) 1648 (-18000) 1639 (-17000) 1630
			(-16000) 1620 (-15000) 1610 (-14000) 1599
			(-13000) 1588 (-12000) 1577 (-11000) 1565
			(-10000) 1553 (-9000) 1540 (-8000) 1527
			(-7000) 1514 (-6000) 1500 (-5000) 1485
			(-4000) 1470 (-3000) 1455 (-2000) 1439
			(-1000) 1423 (0) 1406 (1000) 1389
			(2000) 1372 (3000) 1354 (4000) 1335
			(5000) 1317 (6000) 1298 (7000) 1279
			(8000) 1259 (9000) 1239 (10000) 1219
			(11000) 1198 (12000) 1178 (13000) 1157
			(14000) 1136 (15000) 1115 (16000) 1093
			(17000) 1072 (18000) 1050 (19000) 1029
			(20000) 1007 (21000) 986 (22000) 964
			(23000) 943 (24000) 921 (25000) 900
			(26000) 879 (27000) 858 (28000) 837
			(29000) 816 (30000) 796 (31000) 775
			(32000) 755 (33000) 736 (34000) 716
			(35000) 697 (36000) 678 (37000) 659
			(38000) 641 (39000) 623 (40000) 605
			(41000) 588 (42000) 571 (43000) 555
			(44000) 538 (45000) 523 (46000) 507
			(47000) 492 (48000) 477 (49000) 463
			(50000) 449 (51000) 435 (52000) 422
			(53000) 409 (54000) 396 (55000) 384
			(56000) 372 (57000) 360 (58000) 349
			(59000) 338 (60000) 327 (61000) 317
			(62000) 307 (63000) 297 (64000) 288
			(65000) 279 (66000) 270 (67000) 261
			(68000) 253 (69000) 245 (70000) 237
			(71000) 230 (72000) 222 (73000) 215
			(74000) 209 (75000) 202 (76000) 196
			(77000) 189 (78000) 183 (79000) 178
			(80000) 172 (81000) 167 (82000) 161
			(83000) 156 (84000) 151 (85000) 147
			(86000) 142 (87000) 138 (88000) 133
			(89000) 129 (90000) 125 (91000) 121
			(92000) 118 (93000) 114 (94000) 111
			(95000) 107 (96000) 104 (97000) 101
			(98000) 98 (99000) 95 (100000) 92
			(101000) 89 (102000) 87 (103000) 84
			(104000) 81 (105000) 79 (106000) 77
			(107000) 74 (108000) 72 (109000) 70
			(110000) 68 (111000) 66 (112000) 64
			(113000) 62 (114000) 61 (115000) 59
			(116000) 57 (117000) 56 (118000) 54
			(119000) 52 (120000) 51 (121000) 50
			(122000) 48 (123000) 47 (124000) 46
			(125000) 44
		>;
	};

	thermal_zones: thermal-zones {
		cpu0-thermal {
			polling-delay = <1000>;
			polling-delay-passive = <150>;
			thermal-sensors = <&lvts MT6789_LITTLE_CPU0>;

			trips {
				cpu0_alert: trip-alert {
					temperature = <85000>;
					hysteresis = <2000>;
					type = "passive";
				};

				cpu0_crit: trip-crit {
					temperature = <113500>;
					hysteresis = <2000>;
					type = "critical";
				};
			};

			cooling-maps {
				map0 {
					trip = <&cpu0_alert>;
					cooling-device = <&cpu0 THERMAL_NO_LIMIT THERMAL_NO_LIMIT>,
							 <&cpu1 THERMAL_NO_LIMIT THERMAL_NO_LIMIT>,
							 <&cpu2 THERMAL_NO_LIMIT THERMAL_NO_LIMIT>,
							 <&cpu3 THERMAL_NO_LIMIT THERMAL_NO_LIMIT>,
							 <&cpu4 THERMAL_NO_LIMIT THERMAL_NO_LIMIT>,
							 <&cpu5 THERMAL_NO_LIMIT THERMAL_NO_LIMIT>;
				};
			};
		};

		cpu1-thermal {
			polling-delay = <1000>;
			polling-delay-passive = <150>;
			thermal-sensors = <&lvts MT6789_LITTLE_CPU1>;

			trips {
				cpu1_alert: trip-alert {
					temperature = <85000>;
					hysteresis = <2000>;
					type = "passive";
				};

				cpu1_crit: trip-crit {
					temperature = <113500>;
					hysteresis = <2000>;
					type = "critical";
				};
			};

			cooling-maps {
				map0 {
					trip = <&cpu1_alert>;
					cooling-device = <&cpu0 THERMAL_NO_LIMIT THERMAL_NO_LIMIT>,
							 <&cpu1 THERMAL_NO_LIMIT THERMAL_NO_LIMIT>,
							 <&cpu2 THERMAL_NO_LIMIT THERMAL_NO_LIMIT>,
							 <&cpu3 THERMAL_NO_LIMIT THERMAL_NO_LIMIT>,
							 <&cpu4 THERMAL_NO_LIMIT THERMAL_NO_LIMIT>,
							 <&cpu5 THERMAL_NO_LIMIT THERMAL_NO_LIMIT>;
				};
			};
		};

		cpu2-thermal {
			polling-delay = <1000>;
			polling-delay-passive = <150>;
			thermal-sensors = <&lvts MT6789_LITTLE_CPU2>;

			trips {
				cpu2_alert: trip-alert {
					temperature = <85000>;
					hysteresis = <2000>;
					type = "passive";
				};

				cpu2_crit: trip-crit {
					temperature = <113500>;
					hysteresis = <2000>;
					type = "critical";
				};
			};

			cooling-maps {
				map0 {
					trip = <&cpu2_alert>;
					cooling-device = <&cpu0 THERMAL_NO_LIMIT THERMAL_NO_LIMIT>,
							 <&cpu1 THERMAL_NO_LIMIT THERMAL_NO_LIMIT>,
							 <&cpu2 THERMAL_NO_LIMIT THERMAL_NO_LIMIT>,
							 <&cpu3 THERMAL_NO_LIMIT THERMAL_NO_LIMIT>,
							 <&cpu4 THERMAL_NO_LIMIT THERMAL_NO_LIMIT>,
							 <&cpu5 THERMAL_NO_LIMIT THERMAL_NO_LIMIT>;
				};
			};
		};

		cpu3-thermal {
			polling-delay = <1000>;
			polling-delay-passive = <150>;
			thermal-sensors = <&lvts MT6789_LITTLE_CPU3>;

			trips {
				cpu3_alert: trip-alert {
					temperature = <85000>;
					hysteresis = <2000>;
					type = "passive";
				};

				cpu3_crit: trip-crit {
					temperature = <113500>;
					hysteresis = <2000>;
					type = "critical";
				};
			};

			cooling-maps {
				map0 {
					trip = <&cpu3_alert>;
					cooling-device = <&cpu0 THERMAL_NO_LIMIT THERMAL_NO_LIMIT>,
							 <&cpu1 THERMAL_NO_LIMIT THERMAL_NO_LIMIT>,
							 <&cpu2 THERMAL_NO_LIMIT THERMAL_NO_LIMIT>,
							 <&cpu3 THERMAL_NO_LIMIT THERMAL_NO_LIMIT>,
							 <&cpu4 THERMAL_NO_LIMIT THERMAL_NO_LIMIT>,
							 <&cpu5 THERMAL_NO_LIMIT THERMAL_NO_LIMIT>;
				};
			};
		};

		cpu4-thermal {
			polling-delay = <1000>;
			polling-delay-passive = <150>;
			thermal-sensors = <&lvts MT6789_BIG_CPU0>;

			trips {
				cpu4_alert: trip-alert {
					temperature = <85000>;
					hysteresis = <2000>;
					type = "passive";
				};

				cpu4_crit: trip-crit {
					temperature = <113500>;
					hysteresis = <2000>;
					type = "critical";
				};
			};

			cooling-maps {
				map0 {
					trip = <&cpu4_alert>;
					cooling-device = <&cpu6 THERMAL_NO_LIMIT THERMAL_NO_LIMIT>,
							 <&cpu7 THERMAL_NO_LIMIT THERMAL_NO_LIMIT>;
				};
			};
		};

		cpu5-thermal {
			polling-delay = <1000>;
			polling-delay-passive = <150>;
			thermal-sensors = <&lvts MT6789_BIG_CPU1>;

			trips {
				cpu5_alert: trip-alert {
					temperature = <85000>;
					hysteresis = <2000>;
					type = "passive";
				};

				cpu5_crit: trip-crit {
					temperature = <113500>;
					hysteresis = <2000>;
					type = "critical";
				};
			};

			cooling-maps {
				map0 {
					trip = <&cpu5_alert>;
					cooling-device = <&cpu6 THERMAL_NO_LIMIT THERMAL_NO_LIMIT>,
							 <&cpu7 THERMAL_NO_LIMIT THERMAL_NO_LIMIT>;
				};
			};
		};

		cpu6-thermal {
			polling-delay = <1000>;
			polling-delay-passive = <150>;
			thermal-sensors = <&lvts MT6789_BIG_CPU2>;

			trips {
				cpu6_alert: trip-alert {
					temperature = <85000>;
					hysteresis = <2000>;
					type = "passive";
				};

				cpu6_crit: trip-crit {
					temperature = <113500>;
					hysteresis = <2000>;
					type = "critical";
				};
			};

			cooling-maps {
				map0 {
					trip = <&cpu6_alert>;
					cooling-device = <&cpu6 THERMAL_NO_LIMIT THERMAL_NO_LIMIT>,
							 <&cpu7 THERMAL_NO_LIMIT THERMAL_NO_LIMIT>;
				};
			};
		};

		cpu7-thermal {
			polling-delay = <1000>;
			polling-delay-passive = <150>;
			thermal-sensors = <&lvts MT6789_BIG_CPU3>;

			trips {
				cpu7_alert: trip-alert {
					temperature = <85000>;
					hysteresis = <2000>;
					type = "passive";
				};

				cpu7_crit: trip-crit {
					temperature = <113500>;
					hysteresis = <2000>;
					type = "critical";
				};
			};

			cooling-maps {
				map0 {
					trip = <&cpu7_alert>;
					cooling-device = <&cpu6 THERMAL_NO_LIMIT THERMAL_NO_LIMIT>,
							 <&cpu7 THERMAL_NO_LIMIT THERMAL_NO_LIMIT>;
				};
			};
		};

		gpu1-thermal {
			polling-delay = <1000>;
			polling-delay-passive = <150>;
			thermal-sensors = <&lvts MT6789_GPU0>;

			trips {
				gpu1_alert: trip-alert {
					temperature = <85000>;
					hysteresis = <2000>;
					type = "passive";
				};

				gpu1_crit: trip-crit {
					temperature = <113500>;
					hysteresis = <2000>;
					type = "critical";
				};
			};

			cooling-maps {
				map0 {
					trip = <&gpu1_alert>;
					cooling-device = <&gpu THERMAL_NO_LIMIT THERMAL_NO_LIMIT>;
				};
			};
		};

		gpu2-thermal {
			polling-delay = <1000>;
			polling-delay-passive = <150>;
			thermal-sensors = <&lvts MT6789_GPU1>;

			trips {
				gpu2_alert: trip-alert {
					temperature = <85000>;
					hysteresis = <2000>;
					type = "passive";
				};

				gpu2_crit: trip-crit {
					temperature = <113500>;
					hysteresis = <2000>;
					type = "critical";
				};
			};

			cooling-maps {
				map0 {
					trip = <&gpu2_alert>;
					cooling-device = <&gpu THERMAL_NO_LIMIT THERMAL_NO_LIMIT>;
				};
			};
		};

		soc1-thermal {
			polling-delay = <1000>;
			polling-delay-passive = <150>;
			thermal-sensors = <&lvts MT6789_SOC0>;

			trips {
				soc1_alert: trip-alert {
					temperature = <85000>;
					hysteresis = <2000>;
					type = "passive";
				};

				soc1_crit: trip-crit {
					temperature = <113500>;
					hysteresis = <2000>;
					type = "critical";
				};
			};
		};

		soc2-thermal {
			polling-delay = <1000>;
			polling-delay-passive = <150>;
			thermal-sensors = <&lvts MT6789_SOC1>;

			trips {
				soc2_alert: trip-alert {
					temperature = <85000>;
					hysteresis = <2000>;
					type = "passive";
				};

				soc2_crit: trip-crit {
					temperature = <113500>;
					hysteresis = <2000>;
					type = "critical";
				};
			};
		};

		md-thermal {
			polling-delay = <1000>;
			polling-delay-passive = <150>;
			thermal-sensors = <&lvts MT6789_MD>;

			trips {
				md_alert: trip-alert {
					temperature = <85000>;
					hysteresis = <2000>;
					type = "passive";
				};

				md_crit: trip-crit {
					temperature = <113500>;
					hysteresis = <2000>;
					type = "critical";
				};
			};
		};
	};
};
